# STM32H7A3AGI6Q register map
File version: 1.0
Registers are 32-bit, access not given, reset 0x0 unless marked. A register's access mark holds for its fields unless they carry their own. Offsets are from the block's base; [hi:lo] are bit positions; {n}, {i} and the like mark numbered series; 'fields as' and 'values as' point back to an identical list.

## OCTOSPI1
Base 0x52005000
Same registers: OCTOSPI2 0x5200A000
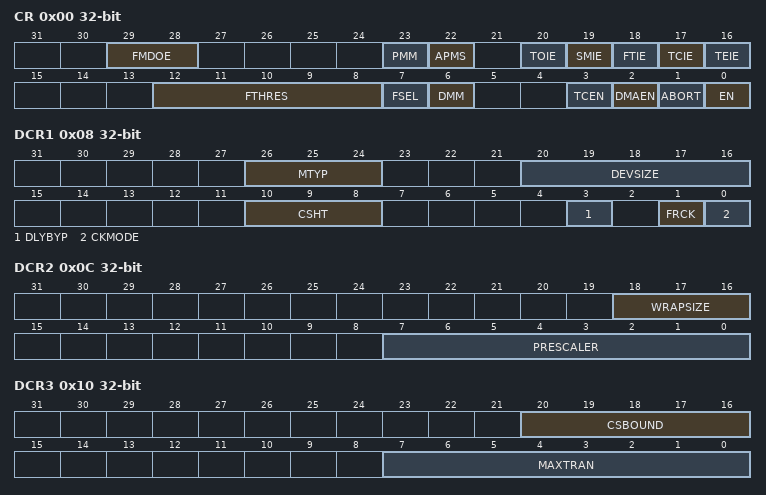
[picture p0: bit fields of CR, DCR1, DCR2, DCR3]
0x00 CR
  [29:28] FMDOE, [23] PMM, [22] APMS, [20] TOIE, [19] SMIE, [18] FTIE, [17] TCIE, [16] TEIE, [12:8] FTHRES, [7] FSEL, [6] DMM, [3] TCEN, [2] DMAEN, [1] ABORT, [0] EN
0x08 DCR1
  [26:24] MTYP, [20:16] DEVSIZE, [10:8] CSHT, [3] DLYBYP, [1] FRCK, [0] CKMODE
0x0C DCR2
  [18:16] WRAPSIZE, [7:0] PRESCALER
0x10 DCR3
  [20:16] CSBOUND, [7:0] MAXTRAN
0x14 DCR4
  [31:0] REFRESH
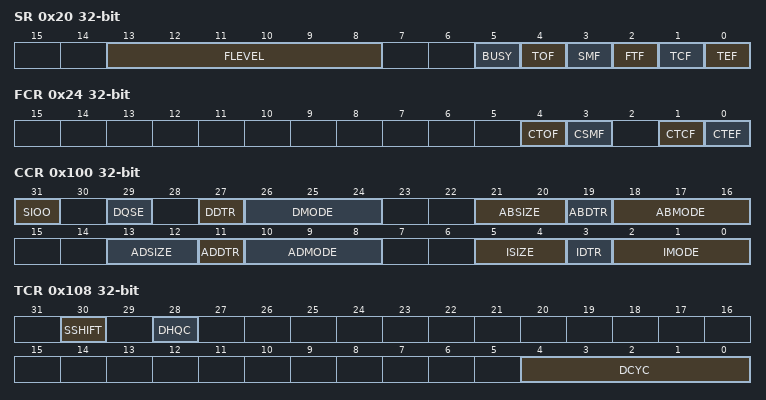
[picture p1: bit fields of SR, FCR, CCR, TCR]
0x20 SR
  [13:8] FLEVEL, [5] BUSY, [4] TOF, [3] SMF, [2] FTF, [1] TCF, [0] TEF
0x24 FCR
  [4] CTOF, [3] CSMF, [1] CTCF, [0] CTEF
0x40 DLR
  [31:0] DL
0x48 AR
  [31:0] ADDRESS
0x50 DR
  [31:0] DATA
0x80 PSMKR
  [31:0] MASK
0x88 PSMAR
  [31:0] MATCH
0x90 PIR
  [15:0] INTERVAL
0x100 CCR
  [31] SIOO, [29] DQSE, [27] DDTR, [26:24] DMODE, [21:20] ABSIZE, [19] ABDTR, [18:16] ABMODE, [13:12] ADSIZE, [11] ADDTR, [10:8] ADMODE, [5:4] ISIZE, [3] IDTR, [2:0] IMODE
0x108 TCR
  [30] SSHIFT, [28] DHQC, [4:0] DCYC
0x110 IR
  [31:0] INSTRUCTION
0x120 ABR
  [31:0] ALTERNATE
0x130 LPTR
  [15:0] TIMEOUT
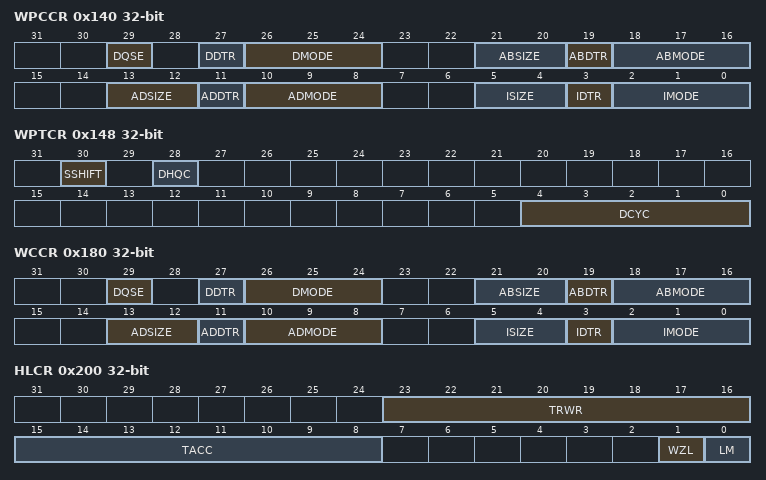
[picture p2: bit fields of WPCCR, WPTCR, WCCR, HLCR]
0x140 WPCCR
  [29] DQSE, [27] DDTR, [26:24] DMODE, [21:20] ABSIZE, [19] ABDTR, [18:16] ABMODE, [13:12] ADSIZE, [11] ADDTR, [10:8] ADMODE, [5:4] ISIZE, [3] IDTR, [2:0] IMODE
0x148 WPTCR
  [30] SSHIFT, [28] DHQC, [4:0] DCYC
0x150 WPIR
  [31:0] INSTRUCTION
0x160 WPABR
  [31:0] ALTERNATE
0x180 WCCR
  fields as WPCCR
0x188 WTCR
  [4:0] DCYC
0x190 WIR
  [31:0] INSTRUCTION
0x1A0 WABR
  [31:0] ALTERNATE
0x200 HLCR
  [23:16] TRWR, [15:8] TACC, [1] WZL, [0] LM

## RAMECC
Base 0x52009000
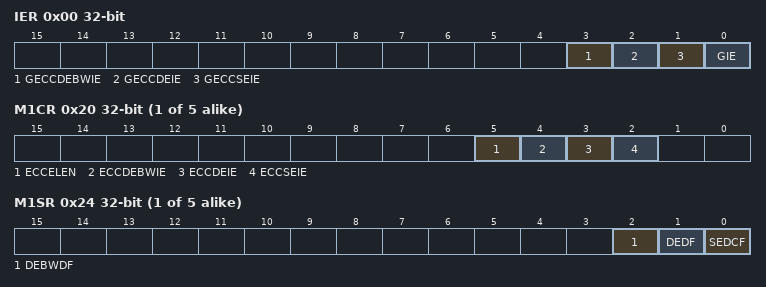
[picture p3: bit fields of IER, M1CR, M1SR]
0x00 IER
  [3] GECCDEBWIE, [2] GECCDEIE, [1] GECCSEIE, [0] GIE
{0x0+0x20*i} M{i}CR (i=1..5)
  [5] ECCELEN, [4] ECCDEBWIE, [3] ECCDEIE, [2] ECCSEIE
{0x4+0x20*i} M{i}SR (i=1..5)
  [2] DEBWDF, [1] DEDF, [0] SEDCF
{0x8+0x20*i} M{i}FAR (i=1..5)
  [31:0] FADD
{0xC+0x20*i} M{i}FDRL (i=1..5)
  [31:0] FDATAL
{0x10+0x20*i} M{i}FDRH (i=1..5)
  [31:0] FDATAH
{0x14+0x20*i} M{i}FECR (i=1..5)
  [31:0] FEC

## OTFDEC1
Base 0x5200B800
Same registers: OTFDEC2 0x5200BC00
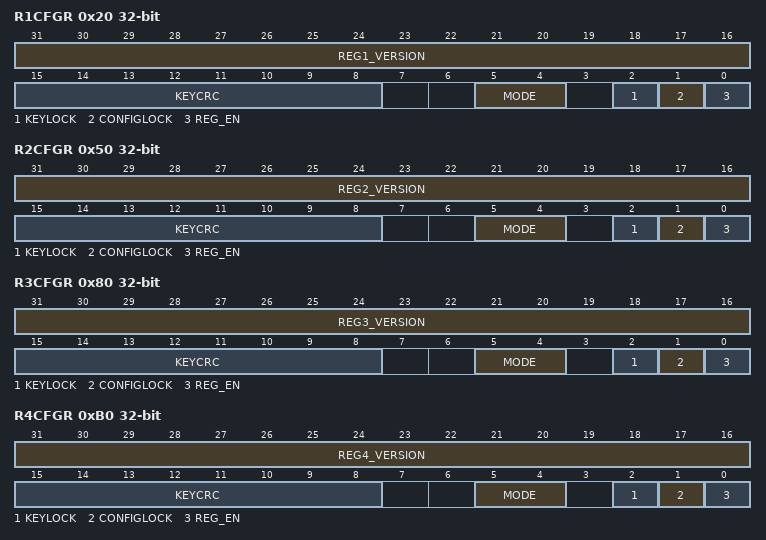
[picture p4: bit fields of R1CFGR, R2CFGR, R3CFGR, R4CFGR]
0x20 R1CFGR
  [31:16] REG1_VERSION, [15:8] KEYCRC, [5:4] MODE, [2] KEYLOCK, [1] CONFIGLOCK, [0] REG_EN
0x24 R1STARTADDR
  [31:0] REG1_START_ADD
0x28 R1ENDADDR
  [31:0] REG1_END_ADD
0x2C R1NONCER0
  [31:0] REG1_NONCE
{0x0+0x30*i} R{i}NONCER1 (i=1..4)
  [31:0] REG{i}_NONCE
{0x34+4i} R1KEYR{i} (i=0..2)
  [31:0] REG1_KEY
0x40 REG1_KEYR3
  [31:0] REG1_KEY
0x50 R2CFGR
  [31:16] REG2_VERSION, [15:8] KEYCRC, [5:4] MODE, [2] KEYLOCK, [1] CONFIGLOCK, [0] REG_EN
0x54 R2STARTADDR
  [31:0] REG2_START_ADD
0x58 R2ENDADDR
  [31:0] REG2_END_ADD
0x5C R2NONCER0
  [31:0] REG2_NONCE
{0x64+4i} R2KEYR{i} (i=0..3)
  [31:0] REG2_KEY
0x80 R3CFGR
  [31:16] REG3_VERSION, [15:8] KEYCRC, [5:4] MODE, [2] KEYLOCK, [1] CONFIGLOCK, [0] REG_EN
0x84 R3STARTADDR
  [31:0] REG3_START_ADD
0x88 R3ENDADDR
  [31:0] REG3_END_ADD
0x8C R3NONCER0
  [31:0] REG3_NONCE
{0x94+4i} R3KEYR{i} (i=0..2)
  [31:0] REG3_KEY
0xA0 REG3_KEYR3
  [31:0] REG3_KEY
0xB0 R4CFGR
  [31:16] REG4_VERSION, [15:8] KEYCRC, [5:4] MODE, [2] KEYLOCK, [1] CONFIGLOCK, [0] REG_EN
0xB4 R4STARTADDR
  [31:0] REG4_START_ADD
0xB8 R4ENDADDR
  [31:0] REG4_END_ADD
0xBC R4NONCER0
  [31:0] REG4_NONCE
{0xC4+4i} R4KEYR{i} (i=0..3)
  [31:0] REG4_KEY
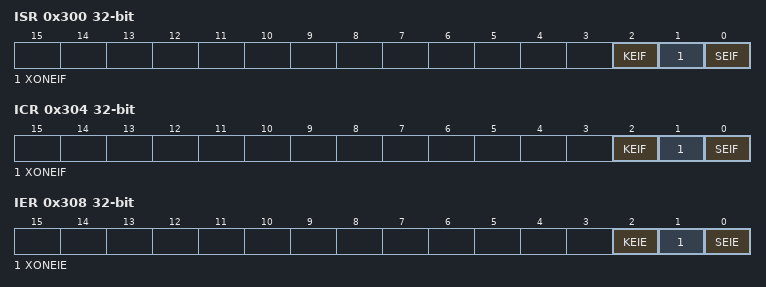
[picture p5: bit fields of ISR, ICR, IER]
0x300 ISR
  [2] KEIF, [1] XONEIF, [0] SEIF
0x304 ICR
  [2] KEIF, [1] XONEIF, [0] SEIF
0x308 IER
  [2] KEIE, [1] XONEIE, [0] SEIE

## GFXMMU
Base 0x5200C000
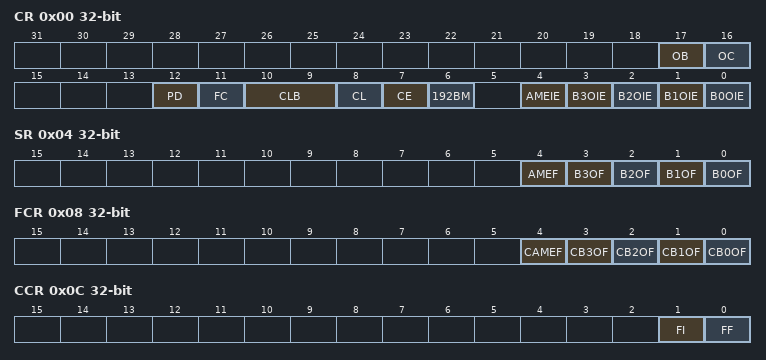
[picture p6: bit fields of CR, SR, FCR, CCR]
0x00 CR
  [17] OB, [16] OC, [12] PD, [11] FC, [10:9] CLB, [8] CL, [7] CE, [6] 192BM, [4] AMEIE, [n] B{n}OIE (n=0..3)
0x04 SR
  [4] AMEF, [n] B{n}OF (n=0..3)
0x08 FCR
  [4] CAMEF, [n] CB{n}OF (n=0..3)
0x0C CCR
  [1] FI, [0] FF
0x10 DVR
  [31:0] DV
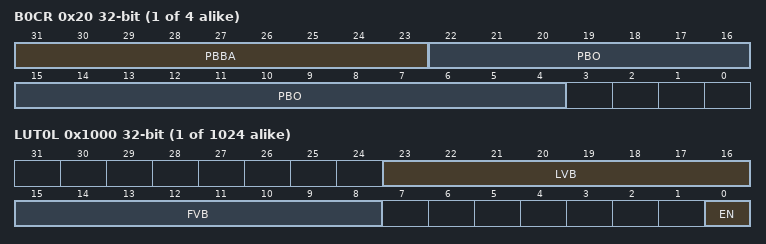
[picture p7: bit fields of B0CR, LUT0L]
{0x20+4i} B{i}CR (i=0..3)
  [31:23] PBBA, [22:4] PBO
{0x1000+8i} LUT{i}L (i=0..1023)
  [23:16] LVB, [15:8] FVB, [0] EN
{0x1004+8i} LUT{i}H (i=0..1023)
  [21:4] LO
